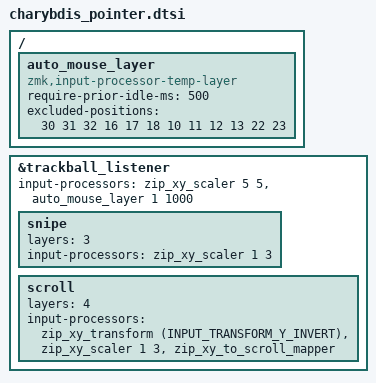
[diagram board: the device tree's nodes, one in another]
#include <input/processors.dtsi>
#include <dt-bindings/zmk/input_transform.h>

&trackball_listener {
    /* Move the pointer and temporarily expose mouse buttons on layer 1. */
    input-processors = <&zip_xy_scaler 5 5>, <&auto_mouse_layer 1 1000>;

    /* Slow pointer movement on the Number layer. */
    snipe: snipe {
        layers           = <3>;
        input-processors = <&zip_xy_scaler 1 3>;
    };

    /* Scroll with the trackball on the Function layer. */
    scroll: scroll {
        layers           = <4>;
        input-processors = <
            &zip_xy_transform (INPUT_TRANSFORM_Y_INVERT)
            &zip_xy_scaler 1 3
            &zip_xy_to_scroll_mapper
        >;
    };
};

/ {
    auto_mouse_layer: auto_mouse_layer {
        compatible = "zmk,input-processor-temp-layer";
        #input-processor-cells = <2>;
        require-prior-idle-ms = <500>;
        excluded-positions = <30 31 32 16 17 18 10 11 12 13 22 23>;
    };
};
